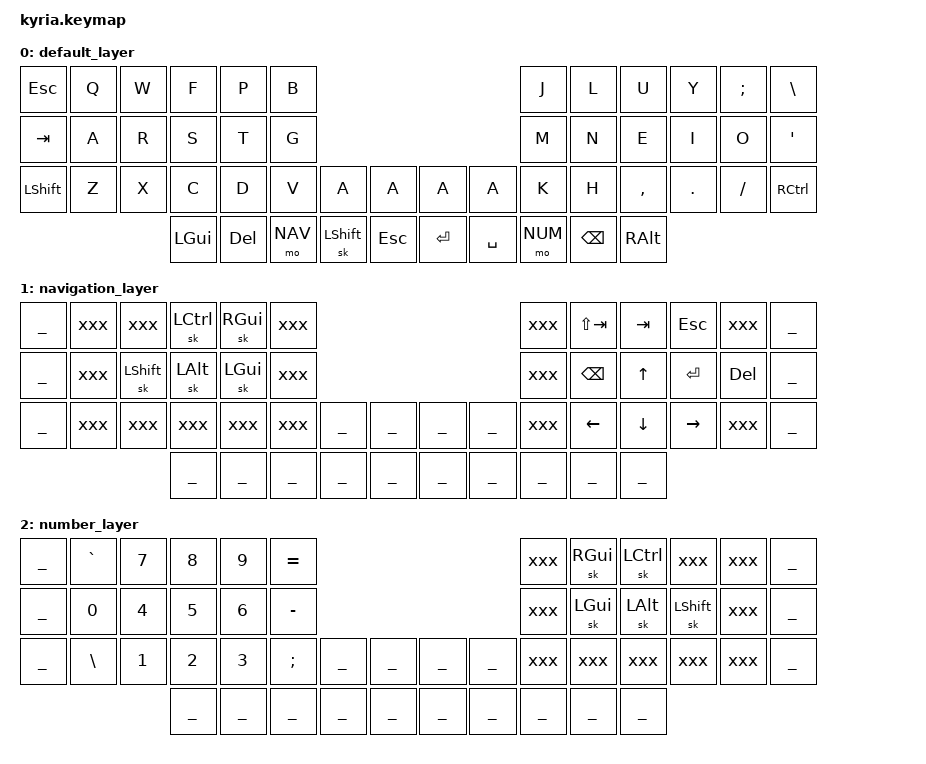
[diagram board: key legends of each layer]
#include <behaviors.dtsi>
#include <dt-bindings/zmk/keys.h>
#include "aliases.h"

/ {
  keymap {
    compatible = "zmk,keymap";
  
    default_layer {
      bindings = <
   &kp ESC      &kp Q      &kp W      &kp F       &kp P      &kp B                                                        &kp J      &kp L      &kp U       &kp Y      &kp SEMI   &kp BSLH
   &kp TAB      &kp A      &kp R      &kp S       &kp T      &kp G                                                        &kp M      &kp N      &kp E       &kp I      &kp O      &kp SQT
   &kp LSHFT    &kp Z      &kp X      &kp C       &kp D      &kp V      &kp A        &kp A           &kp A     &kp A      &kp K      &kp H      &kp COMMA   &kp DOT    &kp FSLH   &kp RCTRL
                                      &kp LGUI    &kp DEL    &mo NAV    &sk LSHIFT   &kp ESC         &kp RET   &kp SPACE  &mo NUM    &kp BSPC   &kp RALT
      >;
      sensor-bindings = <&inc_dec_kp C_VOL_UP C_VOL_DN &inc_dec_kp PG_UP PG_DN>;
    };


    navigation_layer {
      bindings = <
    ___   xxx   xxx           &sk LCTRL     &sk RGUI      xxx                                xxx   &kp LS(TAB)   &kp TAB       &kp ESC       xxx           ___
    ___   xxx   &sk LSHIFT    &sk LALT      &sk LGUI      xxx                                xxx   &kp BSPC      &kp UP        &kp ENTER     &kp DEL       ___
    ___   xxx   xxx           xxx           xxx           xxx   ___    ___       ___   ___   xxx   &kp LEFT      &kp DOWN      &kp RIGHT     xxx           ___
                              ___           ___           ___   ___    ___       ___   ___   ___   ___           ___
      >;
      sensor-bindings = <&inc_dec_kp C_VOL_UP C_VOL_DN &inc_dec_kp PG_UP PG_DN>;
    };

    number_layer {
      bindings = <
      ___   &kp GRAVE    &kp N7   &kp N8   &kp N9   &kp EQUAL                                  xxx   &sk RGUI      &sk LCTRL     xxx         xxx           ___
      ___   &kp N0       &kp N4   &kp N5   &kp N6   &kp MINUS                                  xxx   &sk LGUI      &sk LALT      &sk LSHIFT  xxx           ___
      ___   &kp BSLH     &kp N1   &kp N2   &kp N3   &kp SEMI      ___    ___       ___   ___   xxx   xxx           xxx           xxx         xxx           ___
                                  ___      ___      ___           ___    ___       ___   ___   ___   ___           ___
      >;
      sensor-bindings = <&inc_dec_kp C_VOL_UP C_VOL_DN &inc_dec_kp PG_UP PG_DN>;
    };
  };
};
